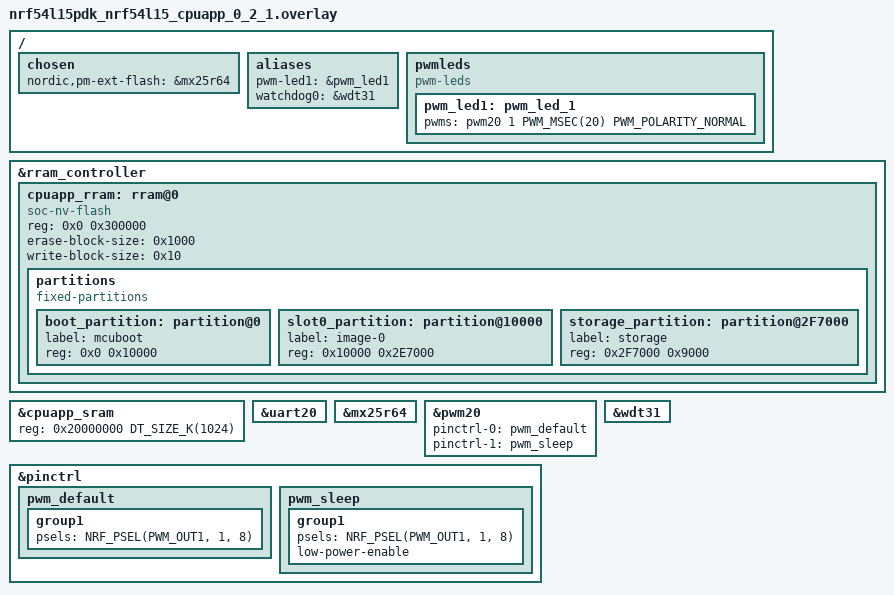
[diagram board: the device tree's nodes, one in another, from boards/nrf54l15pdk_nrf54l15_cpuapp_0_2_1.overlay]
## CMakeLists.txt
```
#
# Copyright (c) 2021 Nordic Semiconductor ASA
#
# SPDX-License-Identifier: LicenseRef-Nordic-5-Clause
#

cmake_minimum_required(VERSION 3.20.0)

find_package(Zephyr HINTS $ENV{ZEPHYR_BASE})

project(matter-light-bulb)

# Enable GNU STD support.
include(${ZEPHYR_CONNECTEDHOMEIP_MODULE_DIR}/config/nrfconnect/app/enable-gnu-std.cmake)

# NORDIC SDK APP START

# Include all source files that are located in the Matter common directory.
include(${ZEPHYR_NRF_MODULE_DIR}/samples/matter/common/cmake/source_common.cmake)

# Include Data Model utils
include(${ZEPHYR_NRF_MODULE_DIR}/samples/matter/common/cmake/data_model.cmake)

target_include_directories(app PRIVATE
    src
)

if(CONFIG_AWS_IOT_INTEGRATION)
    add_subdirectory(src/aws_iot_integration)
endif()

target_sources(app PRIVATE
    src/app_task.cpp
    src/main.cpp
    src/zcl_callbacks.cpp
    ${CHIP_ROOT}/src/app/util/persistence/DeferredAttributePersistenceProvider.cpp
)

ncs_configure_data_model()
# NORDIC SDK APP END
```

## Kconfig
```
#
# Copyright (c) 2022 Nordic Semiconductor
#
# SPDX-License-Identifier: LicenseRef-Nordic-5-Clause
#
mainmenu "Matter nRF Connect Light Bulb Example Application"

# Sample configuration used for Thread networking
if NET_L2_OPENTHREAD

choice OPENTHREAD_NORDIC_LIBRARY_CONFIGURATION
	default OPENTHREAD_NORDIC_LIBRARY_MTD
endchoice

choice OPENTHREAD_DEVICE_TYPE
	default OPENTHREAD_MTD
endchoice

config CHIP_ENABLE_SLEEPY_END_DEVICE_SUPPORT
	bool
	default y

endif # NET_L2_OPENTHREAD

if MPSL_FEM

config OPENTHREAD_DEFAULT_TX_POWER
	int "Set the default 802.15.4 output power (dBm) for device with FEM"
	range -40 20
	default 20
	help
	  Use this setting to set the default Thread (802.15.4) output power for device that
	  uses FEM. This value has a unit in dBm and represents the Tx power at Antenna port of FEM device.

# override FEM GAIN to 20 dB as a default
# see subsys/mpsl/fem/Kconfig
# Leave MPSL_FEM_NRF21540_TX_GAIN_DB unchanged when OPENTHREAD_DEFAULT_TX_POWER=0
# to set the output power to a similar value as for nRF52840DK.
config MPSL_FEM_NRF21540_TX_GAIN_DB
	default 20 if OPENTHREAD_DEFAULT_TX_POWER != 0

endif # MPSL_FEM

source "${ZEPHYR_BASE}/../modules/lib/matter/config/nrfconnect/chip-module/Kconfig.features"
source "${ZEPHYR_BASE}/../modules/lib/matter/config/nrfconnect/chip-module/Kconfig.defaults"
source "Kconfig.zephyr"
```

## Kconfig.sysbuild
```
#
# Copyright (c) 2023 Nordic Semiconductor ASA
#
# SPDX-License-Identifier: LicenseRef-Nordic-5-Clause
#

config PARTITION_MANAGER
	default n if SOC_SERIES_NRF52X || SOC_NRF54L15 || SOC_NRF54LM20A

# This config has to be enabled manually for variants with shields, because sysbuild does not support it.
config WIFI_NRF70
	default y if BOARD_NRF7002DK

#### Radio core selection
config NRF_DEFAULT_IPC_RADIO
	default y

# Enable IEEE802.15.4 serialization to network core
# This config automatically pulls in the `overlay-802154.conf` in the ipc_radio image
config NETCORE_IPC_RADIO_IEEE802154
	default y if SOC_SERIES_NRF53X && !WIFI_NRF70

# Enable Bluetooth serialization to network core
# This config automatically pulls in the `overlay-bt_hci_ipc.conf` in the ipc_radio image
config NETCORE_IPC_RADIO_BT_HCI_IPC
	default y if SOC_SERIES_NRF53X

#### Bootloader
choice BOOTLOADER
	default BOOTLOADER_MCUBOOT if !BOARD_NRF21540DK
endchoice

if BOOTLOADER_MCUBOOT

#### DFU multi-image support
config DFU_MULTI_IMAGE_PACKAGE_BUILD
	default y

config DFU_MULTI_IMAGE_PACKAGE_APP
	default y

config PM_EXTERNAL_FLASH_MCUBOOT_SECONDARY
	default y

#### DFU network core configuration
if SOC_SERIES_NRF53X

choice MCUBOOT_MODE
	default MCUBOOT_MODE_OVERWRITE_ONLY
endchoice

choice BOOT_SIGNATURE_TYPE
	default BOOT_SIGNATURE_TYPE_RSA
endchoice

config SECURE_BOOT_NETCORE
	default y

config NETCORE_APP_UPDATE
	default y

config DFU_MULTI_IMAGE_PACKAGE_NET
	default y

if BOARD_NRF54L15DK || BOARD_NRF54LM20DK

# Disable checking the external drivers for nRF54L15 and nRF54LM20 DKs.
config PM_OVERRIDE_EXTERNAL_DRIVER_CHECK
	default y

endif # BOARD_NRF54L15DK || BOARD_NRF54LM20DK

endif # BOOTLOADER_MCUBOOT

# Store the Wi-Fi firmware patch on external flash by default for nRF5340 with nRF7002
if WIFI_NRF70 && SOC_NRF5340_CPUAPP

choice WIFI_PATCHES_EXT_FLASH_SUPPORT
	default WIFI_PATCHES_EXT_FLASH_STORE

endchoice

config DFU_MULTI_IMAGE_PACKAGE_WIFI_FW_PATCH
	default y

endif # WIFI_NRF70

endif # SOC_SERIES_NRF53X

#### Enable generating factory data
config MATTER_FACTORY_DATA_GENERATE
	default y if !BOARD_NRF21540DK

source "share/sysbuild/Kconfig"
```

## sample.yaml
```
sample:
  description: Matter Light Bulb example
  name: Matter Light Bulb
tests:
  sample.matter.light_bulb.release:
    sysbuild: true
    build_only: true
    extra_args: FILE_SUFFIX=release
      SB_CONFIG_BOOTLOADER_MCUBOOT=y SB_CONFIG_PARTITION_MANAGER=y
    integration_platforms:
      - nrf52840dk/nrf52840
      - nrf5340dk/nrf5340/cpuapp
      - nrf7002dk/nrf5340/cpuapp
      - nrf54l15pdk/nrf54l15/cpuapp
      - nrf54l15pdk@0.3.0/nrf54l15/cpuapp
    platform_allow: nrf52840dk/nrf52840 nrf5340dk/nrf5340/cpuapp nrf7002dk/nrf5340/cpuapp
      nrf54l15pdk/nrf54l15/cpuapp nrf54l15pdk@0.3.0/nrf54l15/cpuapp
    tags: sysbuild
  sample.matter.light_bulb.ffs:
    sysbuild: true
    build_only: true
    extra_args: >
      CONFIG_CHIP_COMMISSIONABLE_DEVICE_TYPE=y CONFIG_CHIP_ROTATING_DEVICE_ID=y
      CONFIG_CHIP_DEVICE_TYPE=257
    integration_platforms:
      - nrf52840dk/nrf52840
      - nrf5340dk/nrf5340/cpuapp
      - nrf7002dk/nrf5340/cpuapp
    platform_allow: nrf52840dk/nrf52840 nrf5340dk/nrf5340/cpuapp nrf7002dk/nrf5340/cpuapp
    tags: sysbuild
  sample.matter.light_bulb.debug.nrf21540ek:
    sysbuild: true
    build_only: true
    extra_args: light_bulb_SHIELD=nrf21540ek
    integration_platforms:
      - nrf52840dk/nrf52840
    platform_allow: nrf52840dk/nrf52840
    tags: sysbuild
  sample.matter.light_bulb.debug.nrf21540ek_fwd:
    sysbuild: true
    build_only: true
    extra_args: light_bulb_SHIELD=nrf21540ek_fwd multiprotocol_rpmsg_SHIELD=nrf21540ek
    integration_platforms:
      - nrf5340dk/nrf5340/cpuapp
    platform_allow: nrf5340dk/nrf5340/cpuapp
    tags: sysbuild
  # Sample to execute load tests
  sample.matter.light_bulb.persistent_subscriptions:
    sysbuild: true
    build_only: true
    extra_args: CONFIG_CHIP_PERSISTENT_SUBSCRIPTIONS=y
    platform_allow: nrf52840dk/nrf52840 nrf5340dk/nrf5340/cpuapp nrf7002dk/nrf5340/cpuapp
    integration_platforms:
      - nrf52840dk/nrf52840
      - nrf5340dk/nrf5340/cpuapp
      - nrf7002dk/nrf5340/cpuapp
    tags: sysbuild
  sample.matter.light_bulb.aws:
    sysbuild: true
    build_only: true
    extra_args: EXTRA_CONF_FILE="overlay-aws-iot-integration.conf"
    platform_allow: nrf7002dk/nrf5340/cpuapp
    integration_platforms:
      - nrf7002dk/nrf5340/cpuapp
    tags: sysbuild
  sample.matter.light_bulb.memory_profiling:
    sysbuild: true
    build_only: true
    extra_args: CONFIG_CHIP_MEMORY_PROFILING=y CONFIG_SHELL_MINIMAL=y
    platform_allow: nrf52840dk/nrf52840 nrf5340dk/nrf5340/cpuapp nrf7002dk/nrf5340/cpuapp
    integration_platforms:
      - nrf52840dk/nrf52840
      - nrf5340dk/nrf5340/cpuapp
      - nrf7002dk/nrf5340/cpuapp
    tags: sysbuild
```

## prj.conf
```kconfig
#
# Copyright (c) 2022 Nordic Semiconductor ASA
#
# SPDX-License-Identifier: LicenseRef-Nordic-5-Clause
#

# Enable CHIP

# Configure ZAP file name
CONFIG_NCS_SAMPLE_MATTER_ZAP_FILE_PATH="${APPLICATION_CONFIG_DIR}/src/default_zap/light_bulb.zap"

# 32773 == 0x8005 (example lighting-app)
CONFIG_CHIP_DEVICE_PRODUCT_ID=32773
CONFIG_STD_CPP17=y

# Enable Matter pairing automatically on application start.
CONFIG_CHIP_ENABLE_PAIRING_AUTOSTART=y

# Enable Matter extended announcement and increase duration to 1 hour.
CONFIG_CHIP_BLE_EXT_ADVERTISING=y
CONFIG_CHIP_BLE_ADVERTISING_DURATION=60

# Add support for LEDs and buttons on Nordic development kits
CONFIG_DK_LIBRARY=y
CONFIG_PWM=y

# Bluetooth Low Energy configuration
CONFIG_BT_DEVICE_NAME="MatterLight"

# Other settings
CONFIG_THREAD_NAME=y
CONFIG_MPU_STACK_GUARD=y
CONFIG_RESET_ON_FATAL_ERROR=n
CONFIG_CHIP_LIB_SHELL=y
CONFIG_NCS_SAMPLE_MATTER_TEST_SHELL=y

# Reduce application size
CONFIG_USE_SEGGER_RTT=n

# Enable Factory Data feature
CONFIG_CHIP_FACTORY_DATA=y
CONFIG_CHIP_FACTORY_DATA_BUILD=y
```

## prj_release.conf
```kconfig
#
# Copyright (c) 2022 Nordic Semiconductor ASA
#
# SPDX-License-Identifier: LicenseRef-Nordic-5-Clause
#

# Enable CHIP
CONFIG_CHIP=y
CONFIG_CHIP_PROJECT_CONFIG="src/chip_project_config.h"
# 32773 == 0x8005 (example lighting-app)
CONFIG_CHIP_DEVICE_PRODUCT_ID=32773
CONFIG_STD_CPP17=y

# Enable Matter pairing automatically on application start.
CONFIG_CHIP_ENABLE_PAIRING_AUTOSTART=y

# Enable Matter extended announcement and increase duration to 1 hour.
CONFIG_CHIP_BLE_EXT_ADVERTISING=y
CONFIG_CHIP_BLE_ADVERTISING_DURATION=60

# Add support for LEDs and buttons on Nordic development kits
CONFIG_DK_LIBRARY=y
CONFIG_PWM=y

# Bluetooth Low Energy configuration
CONFIG_BT_DEVICE_NAME="MatterLight"

# Enable system reset on fatal error
CONFIG_RESET_ON_FATAL_ERROR=y

# Disable all debug features
CONFIG_USE_SEGGER_RTT=n
CONFIG_SHELL=n
CONFIG_OPENTHREAD_SHELL=n
CONFIG_CONSOLE=n
CONFIG_UART_CONSOLE=n
CONFIG_SERIAL=n
CONFIG_LOG=n
CONFIG_LOG_MODE_MINIMAL=n
CONFIG_ASSERT_VERBOSE=n
CONFIG_ASSERT_NO_FILE_INFO=y
CONFIG_PRINTK=n
CONFIG_PRINTK_SYNC=n
CONFIG_THREAD_NAME=n
CONFIG_BOOT_BANNER=n

# Enable Factory Data feature
CONFIG_CHIP_FACTORY_DATA=y
CONFIG_CHIP_FACTORY_DATA_BUILD=y

# Enable Watchdog
CONFIG_NCS_MATTER_WATCHDOG=y

# Enable LTO to decrease the flash usage.
CONFIG_LTO=y
CONFIG_ISR_TABLES_LOCAL_DECLARATION=y
```

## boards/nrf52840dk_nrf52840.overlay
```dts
/*
 * Copyright (c) 2021-2022 Nordic Semiconductor ASA
 *
 * SPDX-License-Identifier: LicenseRef-Nordic-5-Clause
 */

#include "../../common/boards/nrf52840dk_nrf52840_partitions.dtsi"

/ {
	/*
	* By default, PWM module is only configured for led0 (LED1 on the board).
	* The light bulb app, however, uses LED2 to show the state of the lighting,
	* including its brightness level.
	*/
	aliases {
		pwm-led1 = &pwm_led1;
	};

	pwmleds {
		pwm_led1: pwm_led_1 {
			pwms = <&pwm0 1 PWM_MSEC(20) PWM_POLARITY_INVERTED>;
		};
	};

};

&pwm0 {
	pinctrl-0 = <&pwm0_default_alt>;
	pinctrl-1 = <&pwm0_sleep_alt>;
	pinctrl-names = "default", "sleep";
};

&pinctrl {
	pwm0_default_alt: pwm0_default_alt {
		group1 {
			psels = <NRF_PSEL(PWM_OUT1, 0, 14)>;
			nordic,invert;
		};
	};

	pwm0_sleep_alt: pwm0_sleep_alt {
		group1 {
			psels = <NRF_PSEL(PWM_OUT1, 0, 14)>;
			low-power-enable;
		};
	};

};

/* Disable unused peripherals to reduce power consumption */
&adc {
	status = "disabled";
};

&uart1 {
	status = "disabled";
};

&i2c0 {
	status = "disabled";
};

&spi1 {
	status = "disabled";
};

&spi3 {
	status = "disabled";
};

&usbd {
	status = "disabled";
};
```

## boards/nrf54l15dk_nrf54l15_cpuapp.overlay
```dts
/*
 * Copyright (c) 2024 Nordic Semiconductor ASA
 *
 * SPDX-License-Identifier: LicenseRef-Nordic-5-Clause
 */

#include "../../common/boards/nrf54l15dk_nrf54l15_cpuapp_partitions.dtsi"

/ {
	aliases {
		/* Configure PWM module for led1 (LED2 on the board) */
		pwm-led1 = &pwm_led1;

		/* Use watchdog wdt31 as the application watchdog */
		watchdog0 = &wdt31;
	};

	pwmleds {
		compatible = "pwm-leds";
		pwm_led1: pwm_led_1 {
			pwms = <&pwm20 1 PWM_MSEC(20) PWM_POLARITY_NORMAL>;
		};
	};
};

/* TODO: re-enable HWFC once it's fixed */
&uart20 {
	/delete-property/ hw-flow-control;
};

&pwm20 {
	status = "okay";
	pinctrl-0 = <&pwm_default>;
	pinctrl-1 = <&pwm_sleep>;
	pinctrl-names = "default", "sleep";
};

&pinctrl {
	pwm_default: pwm_default {
		group1 {
			psels = <NRF_PSEL(PWM_OUT1, 1, 10)>;
		};
	};
	pwm_sleep: pwm_sleep {
		group1 {
			psels = <NRF_PSEL(PWM_OUT1, 1, 10)>;
			low-power-enable;
		};
	};
};

&wdt31 {
	status = "okay";
};
```

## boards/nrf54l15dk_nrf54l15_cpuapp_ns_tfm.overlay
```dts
/*
 * Copyright (c) 2024 Nordic Semiconductor ASA
 *
 * SPDX-License-Identifier: LicenseRef-Nordic-5-Clause
 */

#include <samples/matter/nrf54l15_cpuapp_tfm_base_partitions.dtsi>
#include <samples/matter/nrf54l15_cpuapp_tfm_application_partitions.dtsi>

/ {
	aliases {
		/* Use watchdog wdt31 as the application watchdog */
		watchdog0 = &wdt31;
	};

	chosen {
		nordic,pm-ext-flash = &mx25r64;
	};
};

&mx25r64 {
	status = "okay";
};

&wdt31 {
	status = "okay";
};

/* Change IRQ ids to handle button interrupts.
 * The default values for nRF54L15 are 219 and 269,
 * but with TF-M they are reserved for the secure domain
 * (218 and 268 are reserved for the non-secure domain).
 */
&gpiote20 {
	interrupts = <218 NRF_DEFAULT_IRQ_PRIORITY>;
};

&gpiote30 {
	interrupts = <268 NRF_DEFAULT_IRQ_PRIORITY>;
};
```

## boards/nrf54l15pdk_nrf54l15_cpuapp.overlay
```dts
/*
 * Copyright (c) 2024 Nordic Semiconductor ASA
 *
 * SPDX-License-Identifier: LicenseRef-Nordic-5-Clause
 */


/ {
	chosen {
		nordic,pm-ext-flash = &mx25r64;
	};

	aliases {
		// Configure PWM module for led1 (LED2 on the board)
		pwm-led1 = &pwm_led1;

		// Use watchdog wdt31 as the application watchdog
		watchdog0 = &wdt31;
	};

	pwmleds {
		compatible = "pwm-leds";
		pwm_led1: pwm_led_1 {
			pwms = <&pwm20 1 PWM_MSEC(20) PWM_POLARITY_NORMAL>;
		};
	};
};

// Extend RRAM size to 3MB
&cpuapp_rram {
	reg = <0x0 DT_SIZE_K(3072)>;
};

// Extend RAM to 1 MB
&cpuapp_sram {
	reg = <0x20000000 DT_SIZE_K(1024)>;
	ranges = <0x0 0x20000000  0x100000>;
};

// TODO: re-enable HWFC once it's fixed
&uart20 {
	/delete-property/ hw-flow-control;
};

&mx25r64 {
	status = "okay";
};

&pwm20 {
	status = "okay";
	pinctrl-0 = <&pwm_default>;
	pinctrl-1 = <&pwm_sleep>;
	pinctrl-names = "default", "sleep";
};

&pinctrl {
	pwm_default: pwm_default {
		group1 {
			psels = <NRF_PSEL(PWM_OUT1, 1, 10)>;
		};
	};
	pwm_sleep: pwm_sleep {
		group1 {
			psels = <NRF_PSEL(PWM_OUT1, 1, 10)>;
			low-power-enable;
		};
	};
};

&wdt31 {
	status = "okay";
};
```

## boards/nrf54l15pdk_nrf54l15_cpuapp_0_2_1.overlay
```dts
/*
 * Copyright (c) 2024 Nordic Semiconductor ASA
 *
 * SPDX-License-Identifier: LicenseRef-Nordic-5-Clause
 */

/ {
	chosen {
		nordic,pm-ext-flash = &mx25r64;
	};

	aliases {
		// Configure PWM module for led1 (LED2 on the board)
		pwm-led1 = &pwm_led1;

		// Use watchdog wdt31 as the application watchdog
		watchdog0 = &wdt31;
	};

	pwmleds {
		compatible = "pwm-leds";
		pwm_led1: pwm_led_1 {
			pwms = <&pwm20 1 PWM_MSEC(20) PWM_POLARITY_NORMAL>;
		};
	};
};

/delete-node/ &cpuapp_rram;

// Extend RRAM size to 3MB
&rram_controller {
	cpuapp_rram: rram@0 {
		compatible = "soc-nv-flash";
		reg = < 0x0 0x300000 >;
		erase-block-size = < 0x1000 >;
		write-block-size = < 0x10 >;
		partitions {
			compatible = "fixed-partitions";
			#address-cells = < 0x1 >;
			#size-cells = < 0x1 >;
			boot_partition: partition@0 {
				label = "mcuboot";
				reg = < 0x0 0x10000 >;
			};
			slot0_partition: partition@10000 {
				label = "image-0";
				reg = < 0x10000 0x2E7000 >;
			};
			storage_partition: partition@2F7000 {
				label = "storage";
				reg = < 0x2F7000 0x9000 >;
			};
		};
	};
};

// Extend RAM to 1 MB
&cpuapp_sram {
	reg = <0x20000000 DT_SIZE_K(1024)>;
	ranges = <0x0 0x20000000  0x100000>;
};

// TODO: re-enable HWFC once it's fixed
&uart20 {
	/delete-property/ hw-flow-control;
};

&mx25r64 {
	status = "okay";
};

&pwm20 {
	status = "okay";
	pinctrl-0 = <&pwm_default>;
	pinctrl-1 = <&pwm_sleep>;
	pinctrl-names = "default", "sleep";
};

&pinctrl {
	pwm_default: pwm_default {
		group1 {
			psels = <NRF_PSEL(PWM_OUT1, 1, 8)>;
		};
	};
	pwm_sleep: pwm_sleep {
		group1 {
			psels = <NRF_PSEL(PWM_OUT1, 1, 8)>;
			low-power-enable;
		};
	};
};

&wdt31 {
	status = "okay";
};
```

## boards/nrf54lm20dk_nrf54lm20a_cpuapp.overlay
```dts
/*
 * Copyright (c) 2025 Nordic Semiconductor ASA
 *
 * SPDX-License-Identifier: LicenseRef-Nordic-5-Clause
 */

#include "../../common/boards/nrf54lm20dk_nrf54lm20a_cpuapp_partitions.dtsi"

/ {
	aliases {
		/* Configure PWM module for led1 (LED2 on the board) */
		pwm-led1 = &pwm_led1;

		/* Use watchdog wdt31 as the application watchdog */
		watchdog0 = &wdt31;
	};

	pwmleds {
		compatible = "pwm-leds";

		pwm_led1: pwm_led_1 {
			pwms = <&pwm20 1 PWM_MSEC(20) PWM_POLARITY_NORMAL>;
		};
	};
};

&pwm20 {
	status = "okay";
	pinctrl-0 = <&pwm_default>;
	pinctrl-1 = <&pwm_sleep>;
	pinctrl-names = "default", "sleep";
};

&pinctrl {
	pwm_default: pwm_default {
		group1 {
			psels = <NRF_PSEL(PWM_OUT1, 1, 25)>;
		};
	};

	pwm_sleep: pwm_sleep {
		group1 {
			psels = <NRF_PSEL(PWM_OUT1, 1, 25)>;
			low-power-enable;
		};
	};
};

&wdt31 {
	status = "okay";
};
```

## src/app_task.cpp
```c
/*
 * Copyright (c) 2021 Nordic Semiconductor ASA
 *
 * SPDX-License-Identifier: LicenseRef-Nordic-5-Clause
 */

#include "app_task.h"

#include "app_config.h"
#include "led_util.h"
#include "pwm_device.h"

#include <platform/CHIPDeviceLayer.h>

#include <app-common/zap-generated/attribute-id.h>
#include <app-common/zap-generated/attribute-type.h>
#include <app-common/zap-generated/attributes/Accessors.h>
#include <app-common/zap-generated/cluster-id.h>
#include <app/DeferredAttributePersistenceProvider.h>
#include <app/clusters/identify-server/identify-server.h>
#include <app/server/OnboardingCodesUtil.h>
#include <app/server/Server.h>
#include <credentials/DeviceAttestationCredsProvider.h>
#include <credentials/examples/DeviceAttestationCredsExample.h>
#include <lib/support/CHIPMem.h>
#include <lib/support/CodeUtils.h>
#include <system/SystemError.h>

#ifdef CONFIG_CHIP_WIFI
#include <app/clusters/network-commissioning/network-commissioning.h>
#include <platform/nrfconnect/wifi/NrfWiFiDriver.h>
#endif

#ifdef CONFIG_CHIP_OTA_REQUESTOR
#include "ota_util.h"
#endif

#include <dk_buttons_and_leds.h>
#include <zephyr/logging/log.h>
#include <zephyr/kernel.h>

LOG_MODULE_DECLARE(app, CONFIG_MATTER_LOG_LEVEL);

using namespace ::chip;
using namespace ::chip::app;
using namespace ::chip::Credentials;
using namespace ::chip::DeviceLayer;

namespace
{
constexpr uint32_t kFactoryResetTriggerTimeout = 3000;
constexpr uint32_t kFactoryResetCancelWindowTimeout = 3000;
constexpr size_t kAppEventQueueSize = 10;
constexpr EndpointId kLightEndpointId = 1;
constexpr uint8_t kDefaultMinLevel = 0;
constexpr uint8_t kDefaultMaxLevel = 254;
#if NUMBER_OF_BUTTONS == 2
constexpr uint32_t kAdvertisingTriggerTimeout = 3000;
#endif

K_MSGQ_DEFINE(sAppEventQueue, sizeof(AppEvent), kAppEventQueueSize, alignof(AppEvent));
k_timer sFunctionTimer;

Identify sIdentify = { kLightEndpointId, AppTask::IdentifyStartHandler, AppTask::IdentifyStopHandler,
		       EMBER_ZCL_IDENTIFY_IDENTIFY_TYPE_VISIBLE_LED };

LEDWidget sStatusLED;
LEDWidget sIdentifyLED;
#if NUMBER_OF_LEDS == 4
FactoryResetLEDsWrapper<2> sFactoryResetLEDs{ { FACTORY_RESET_SIGNAL_LED, FACTORY_RESET_SIGNAL_LED1 } };
#endif

bool sIsNetworkProvisioned = false;
bool sIsNetworkEnabled = false;
bool sHaveBLEConnections = false;

const struct pwm_dt_spec sLightPwmDevice = PWM_DT_SPEC_GET(DT_ALIAS(pwm_led1));

// Define a custom attribute persister which makes actual write of the CurrentLevel attribute value
// to the non-volatile storage only when it has remained constant for 5 seconds. This is to reduce
// the flash wearout when the attribute changes frequently as a result of MoveToLevel command.
// DeferredAttribute object describes a deferred attribute, but also holds a buffer with a value to
// be written, so it must live so long as the DeferredAttributePersistenceProvider object.
DeferredAttribute gCurrentLevelPersister(ConcreteAttributePath(kLightEndpointId, Clusters::LevelControl::Id,
							       Clusters::LevelControl::Attributes::CurrentLevel::Id));
DeferredAttributePersistenceProvider gDeferredAttributePersister(Server::GetInstance().GetDefaultAttributePersister(),
								 Span<DeferredAttribute>(&gCurrentLevelPersister, 1),
								 System::Clock::Milliseconds32(5000));

} /* namespace */

namespace LedConsts
{
constexpr uint32_t kBlinkRate_ms{ 500 };
constexpr uint32_t kIdentifyBlinkRate_ms{ 500 };

namespace StatusLed
{
	namespace Unprovisioned
	{
		constexpr uint32_t kOn_ms{ 100 };
		constexpr uint32_t kOff_ms{ kOn_ms };
	} /* namespace Unprovisioned */
	namespace Provisioned
	{
		constexpr uint32_t kOn_ms{ 50 };
		constexpr uint32_t kOff_ms{ 950 };
	} /* namespace Provisioned */

} /* namespace StatusLed */
} /* namespace LedConsts */

#ifdef CONFIG_CHIP_WIFI
app::Clusters::NetworkCommissioning::Instance
	sWiFiCommissioningInstance(0, &(NetworkCommissioning::NrfWiFiDriver::Instance()));
#endif

CHIP_ERROR AppTask::Init()
{
	/* Initialize CHIP stack */
	LOG_INF("Init CHIP stack");

	CHIP_ERROR err = chip::Platform::MemoryInit();
	if (err != CHIP_NO_ERROR) {
		LOG_ERR("Platform::MemoryInit() failed");
		return err;
	}

	err = PlatformMgr().InitChipStack();
	if (err != CHIP_NO_ERROR) {
		LOG_ERR("PlatformMgr().InitChipStack() failed");
		return err;
	}

#if defined(CONFIG_NET_L2_OPENTHREAD)
	err = ThreadStackMgr().InitThreadStack();
	if (err != CHIP_NO_ERROR) {
		LOG_ERR("ThreadStackMgr().InitThreadStack() failed: %s", ErrorStr(err));
		return err;
	}

	err = ConnectivityMgr().SetThreadDeviceType(ConnectivityManager::kThreadDeviceType_Router);

	if (err != CHIP_NO_ERROR) {
		LOG_ERR("ThreadStackMgr().InitThreadStack() failed: %s", ErrorStr(err));
		return err;
	}

#elif defined(CONFIG_CHIP_WIFI)
	sWiFiCommissioningInstance.Init();
#else
	return CHIP_ERROR_INTERNAL;
#endif /* CONFIG_NET_L2_OPENTHREAD */

	/* Initialize LEDs */
	LEDWidget::InitGpio();
	LEDWidget::SetStateUpdateCallback(LEDStateUpdateHandler);

	sStatusLED.Init(SYSTEM_STATE_LED);
	sIdentifyLED.Init(LIGHTING_STATE_LED);
	sIdentifyLED.Set(false);

	UpdateStatusLED();

	/* Initialize buttons */
	int ret = dk_buttons_init(ButtonEventHandler);
	if (ret) {
		LOG_ERR("dk_buttons_init() failed");
		return chip::System::MapErrorZephyr(ret);
	}

	/* Initialize function timer */
	k_timer_init(&sFunctionTimer, &AppTask::FunctionTimerTimeoutCallback, nullptr);
	k_timer_user_data_set(&sFunctionTimer, this);

#ifdef CONFIG_MCUMGR_SMP_BT
	/* Initialize DFU over SMP */
	GetDFUOverSMP().Init(RequestSMPAdvertisingStart);
	GetDFUOverSMP().ConfirmNewImage();
#endif

	/* Initialize lighting device (PWM) */
	uint8_t minLightLevel = kDefaultMinLevel;
	Clusters::LevelControl::Attributes::MinLevel::Get(kLightEndpointId, &minLightLevel);

	uint8_t maxLightLevel = kDefaultMaxLevel;
	Clusters::LevelControl::Attributes::MaxLevel::Get(kLightEndpointId, &maxLightLevel);

	ret = mPWMDevice.Init(&sLightPwmDevice, minLightLevel, maxLightLevel, maxLightLevel);
	if (ret != 0) {
		return chip::System::MapErrorZephyr(ret);
	}
	mPWMDevice.SetCallbacks(ActionInitiated, ActionCompleted);

	/* Initialize CHIP server */
#if CONFIG_CHIP_FACTORY_DATA
	ReturnErrorOnFailure(mFactoryDataProvider.Init());
	SetDeviceInstanceInfoProvider(&mFactoryDataProvider);
	SetDeviceAttestationCredentialsProvider(&mFactoryDataProvider);
	SetCommissionableDataProvider(&mFactoryDataProvider);
#else
	SetDeviceAttestationCredentialsProvider(Examples::GetExampleDACProvider());
#endif

	static CommonCaseDeviceServerInitParams initParams;
	(void)initParams.InitializeStaticResourcesBeforeServerInit();

	ReturnErrorOnFailure(chip::Server::GetInstance().Init(initParams));
	app::SetAttributePersistenceProvider(&gDeferredAttributePersister);
	ConfigurationMgr().LogDeviceConfig();
	PrintOnboardingCodes(chip::RendezvousInformationFlags(chip::RendezvousInformationFlag::kBLE));

	/*
	 * Add CHIP event handler and start CHIP thread.
	 * Note that all the initialization code should happen prior to this point to avoid data races
	 * between the main and the CHIP threads.
	 */
	PlatformMgr().AddEventHandler(ChipEventHandler, 0);

	err = PlatformMgr().StartEventLoopTask();
	if (err != CHIP_NO_ERROR) {
		LOG_ERR("PlatformMgr().StartEventLoopTask() failed");
		return err;
	}

	return CHIP_NO_ERROR;
}

CHIP_ERROR AppTask::StartApp()
{
	ReturnErrorOnFailure(Init());

	AppEvent event = {};

	while (true) {
		k_msgq_get(&sAppEventQueue, &event, K_FOREVER);
		DispatchEvent(event);
	}

	return CHIP_NO_ERROR;
}

void AppTask::IdentifyStartHandler(Identify *)
{
	AppEvent event;
	event.Type = AppEventType::IdentifyStart;
	event.Handler = [](const AppEvent &) {
		Instance().mPWMDevice.SuppressOutput();
		sIdentifyLED.Blink(LedConsts::kIdentifyBlinkRate_ms);
	};
	PostEvent(event);
}

void AppTask::IdentifyStopHandler(Identify *)
{
	AppEvent event;
	event.Type = AppEventType::IdentifyStop;
	event.Handler = [](const AppEvent &) {
		sIdentifyLED.Set(false);
		Instance().mPWMDevice.ApplyLevel();
	};
	PostEvent(event);
}

#if NUMBER_OF_BUTTONS == 2
void AppTask::StartBLEAdvertisementAndLightActionEventHandler(const AppEvent &event)
{
	if (event.ButtonEvent.Action == static_cast<uint8_t>(AppEventType::ButtonPushed)) {
		Instance().StartTimer(kAdvertisingTriggerTimeout);
		Instance().mFunction = FunctionEvent::AdvertisingStart;
	} else {
		if (Instance().mFunction == FunctionEvent::AdvertisingStart && Instance().mFunctionTimerActive) {
			Instance().CancelTimer();
			Instance().mFunction = FunctionEvent::NoneSelected;

			AppEvent button_event;
			button_event.Type = AppEventType::Button;
			button_event.ButtonEvent.PinNo = BLE_ADVERTISEMENT_START_AND_LIGHTING_BUTTON;
			button_event.ButtonEvent.Action = static_cast<uint8_t>(AppEventType::ButtonReleased);
			button_event.Handler = LightingActionEventHandler;
			PostEvent(button_event);
		}
	}
}
#endif

void AppTask::LightingActionEventHandler(const AppEvent &event)
{
	PWMDevice::Action_t action = PWMDevice::INVALID_ACTION;
	int32_t actor = 0;

	if (event.Type == AppEventType::Lighting) {
		action = static_cast<PWMDevice::Action_t>(event.LightingEvent.Action);
		actor = event.LightingEvent.Actor;
	} else if (event.Type == AppEventType::Button) {
		action = Instance().mPWMDevice.IsTurnedOn() ? PWMDevice::OFF_ACTION : PWMDevice::ON_ACTION;
		actor = static_cast<int32_t>(AppEventType::Button);
	}

	if (action != PWMDevice::INVALID_ACTION && Instance().mPWMDevice.InitiateAction(action, actor, NULL)) {
		LOG_INF("Action is already in progress or active.");
	}
}

void AppTask::ButtonEventHandler(uint32_t buttonState, uint32_t hasChanged)
{
	AppEvent button_event;
	button_event.Type = AppEventType::Button;

#if NUMBER_OF_BUTTONS == 2
	if (BLE_ADVERTISEMENT_START_AND_LIGHTING_BUTTON_MASK & hasChanged) {
		button_event.ButtonEvent.PinNo = BLE_ADVERTISEMENT_START_AND_LIGHTING_BUTTON;
		button_event.ButtonEvent.Action =
			static_cast<uint8_t>((BLE_ADVERTISEMENT_START_AND_LIGHTING_BUTTON_MASK & buttonState) ?
						     AppEventType::ButtonPushed :
						     AppEventType::ButtonReleased);
		button_event.Handler = StartBLEAdvertisementAndLightActionEventHandler;
		PostEvent(button_event);
	}
#else
	if (LIGHTING_BUTTON_MASK & buttonState & hasChanged) {
		button_event.ButtonEvent.PinNo = LIGHTING_BUTTON;
		button_event.ButtonEvent.Action = static_cast<uint8_t>(AppEventType::ButtonPushed);
		button_event.Handler = LightingActionEventHandler;
		PostEvent(button_event);
	}

	if (BLE_ADVERTISEMENT_START_BUTTON_MASK & buttonState & hasChanged) {
		button_event.ButtonEvent.PinNo = BLE_ADVERTISEMENT_START_BUTTON;
		button_event.ButtonEvent.Action = static_cast<uint8_t>(AppEventType::ButtonPushed);
		button_event.Handler = StartBLEAdvertisementHandler;
		PostEvent(button_event);
	}
#endif

	if (FUNCTION_BUTTON_MASK & hasChanged) {
		button_event.ButtonEvent.PinNo = FUNCTION_BUTTON;
		button_event.ButtonEvent.Action =
			static_cast<uint8_t>((FUNCTION_BUTTON_MASK & buttonState) ? AppEventType::ButtonPushed :
										    AppEventType::ButtonReleased);
		button_event.Handler = FunctionHandler;
		PostEvent(button_event);
	}
}

void AppTask::FunctionTimerTimeoutCallback(k_timer *timer)
{
	if (!timer) {
		return;
	}

	Instance().mFunctionTimerActive = false;
	AppEvent event;
	event.Type = AppEventType::Timer;
	event.TimerEvent.Context = k_timer_user_data_get(timer);
	event.Handler = FunctionTimerEventHandler;
	PostEvent(event);
}

void AppTask::FunctionTimerEventHandler(const AppEvent &event)
{
	if (event.Type != AppEventType::Timer) {
		return;
	}

	/* If we reached here, the button was held past kFactoryResetTriggerTimeout, initiate factory reset */
	if (Instance().mFunction == FunctionEvent::SoftwareUpdate) {
		LOG_INF("Factory Reset Triggered. Release button within %ums to cancel.", kFactoryResetTriggerTimeout);

		/* Start timer for kFactoryResetCancelWindowTimeout to allow user to cancel, if required. */
		Instance().StartTimer(kFactoryResetCancelWindowTimeout);
		Instance().mFunction = FunctionEvent::FactoryReset;

		/* Turn off all LEDs before starting blink to make sure blink is co-ordinated. */
		sStatusLED.Set(false);
#if NUMBER_OF_LEDS == 4
		sFactoryResetLEDs.Set(false);
#endif

		sStatusLED.Blink(LedConsts::kBlinkRate_ms);
#if NUMBER_OF_LEDS == 4
		sFactoryResetLEDs.Blink(LedConsts::kBlinkRate_ms);
#endif
	} else if (Instance().mFunction == FunctionEvent::FactoryReset) {
		/* Actually trigger Factory Reset */
		Instance().mFunction = FunctionEvent::NoneSelected;
		chip::Server::GetInstance().ScheduleFactoryReset();
	} else if (Instance().mFunction == FunctionEvent::AdvertisingStart) {
		/* The button was held past kAdvertisingTriggerTimeout, start BLE advertisement
		   if we have 2 buttons UI*/
#if NUMBER_OF_BUTTONS == 2
		StartBLEAdvertisementHandler(event);
		Instance().mFunction = FunctionEvent::NoneSelected;
#endif
	}
}

#ifdef CONFIG_MCUMGR_SMP_BT
void AppTask::RequestSMPAdvertisingStart(void)
{
	AppEvent event;
	event.Type = AppEventType::StartSMPAdvertising;
	event.Handler = [](const AppEvent &) { GetDFUOverSMP().StartBLEAdvertising(); };
	PostEvent(event);
}
#endif

void AppTask::FunctionHandler(const AppEvent &event)
{
	if (event.ButtonEvent.PinNo != FUNCTION_BUTTON)
		return;

	/* To trigger software update: press the FUNCTION_BUTTON button briefly (< kFactoryResetTriggerTimeout)
	 * To initiate factory reset: press the FUNCTION_BUTTON for kFactoryResetTriggerTimeout +
	 * kFactoryResetCancelWindowTimeout All LEDs start blinking after kFactoryResetTriggerTimeout to signal factory
	 * reset has been initiated. To cancel factory reset: release the FUNCTION_BUTTON once all LEDs start blinking
	 * within the kFactoryResetCancelWindowTimeout.
	 */
	if (event.ButtonEvent.Action == static_cast<uint8_t>(AppEventType::ButtonPushed)) {
		if (!Instance().mFunctionTimerActive && Instance().mFunction == FunctionEvent::NoneSelected) {
			Instance().StartTimer(kFactoryResetTriggerTimeout);
			Instance().mFunction = FunctionEvent::SoftwareUpdate;
		}
	} else {
		/* If the button was released before factory reset got initiated, trigger a software update. */
		if (Instance().mFunctionTimerActive && Instance().mFunction == FunctionEvent::SoftwareUpdate) {
			Instance().CancelTimer();
			Instance().mFunction = FunctionEvent::NoneSelected;

#ifdef CONFIG_MCUMGR_SMP_BT
			GetDFUOverSMP().StartServer();
#else
			LOG_INF("Software update is disabled");
#endif
		} else if (Instance().mFunctionTimerActive && Instance().mFunction == FunctionEvent::FactoryReset) {
#if NUMBER_OF_LEDS == 4
			sFactoryResetLEDs.Set(false);
#endif
			UpdateStatusLED();
			Instance().CancelTimer();
			Instance().mFunction = FunctionEvent::NoneSelected;
			LOG_INF("Factory Reset has been Canceled");
		}
	}
}

void AppTask::StartBLEAdvertisementHandler(const AppEvent &)
{
	if (Server::GetInstance().GetFabricTable().FabricCount() != 0) {
		LOG_INF("Matter service BLE advertising not started - device is already commissioned");
		return;
	}

	if (ConnectivityMgr().IsBLEAdvertisingEnabled()) {
		LOG_INF("BLE advertising is already enabled");
		return;
	}

	if (Server::GetInstance().GetCommissioningWindowManager().OpenBasicCommissioningWindow() != CHIP_NO_ERROR) {
		LOG_ERR("OpenBasicCommissioningWindow() failed");
	}
}

void AppTask::UpdateLedStateEventHandler(const AppEvent &event)
{
	if (event.Type == AppEventType::UpdateLedState) {
		event.UpdateLedStateEvent.LedWidget->UpdateState();
	}
}

void AppTask::LEDStateUpdateHandler(LEDWidget &ledWidget)
{
	AppEvent event;
	event.Type = AppEventType::UpdateLedState;
	event.Handler = UpdateLedStateEventHandler;
	event.UpdateLedStateEvent.LedWidget = &ledWidget;
	PostEvent(event);
}

void AppTask::UpdateStatusLED()
{
	/* Update the status LED.
	 *
	 * If IPv6 network and service provisioned, keep the LED On constantly.
	 *
	 * If the system has ble connection(s) uptill the stage above, THEN blink the LED at an even
	 * rate of 100ms.
	 *
	 * Otherwise, blink the LED for a very short time. */
	if (sIsNetworkProvisioned && sIsNetworkEnabled) {
		sStatusLED.Set(true);
	} else if (sHaveBLEConnections) {
		sStatusLED.Blink(LedConsts::StatusLed::Unprovisioned::kOn_ms,
				 LedConsts::StatusLed::Unprovisioned::kOff_ms);
	} else {
		sStatusLED.Blink(LedConsts::StatusLed::Provisioned::kOn_ms, LedConsts::StatusLed::Provisioned::kOff_ms);
	}
}

void AppTask::ChipEventHandler(const ChipDeviceEvent *event, intptr_t /* arg */)
{
	switch (event->Type) {
	case DeviceEventType::kCHIPoBLEAdvertisingChange:
#ifdef CONFIG_CHIP_NFC_COMMISSIONING
		if (event->CHIPoBLEAdvertisingChange.Result == kActivity_Started) {
			if (NFCMgr().IsTagEmulationStarted()) {
				LOG_INF("NFC Tag emulation is already started");
			} else {
				ShareQRCodeOverNFC(
					chip::RendezvousInformationFlags(chip::RendezvousInformationFlag::kBLE));
			}
		} else if (event->CHIPoBLEAdvertisingChange.Result == kActivity_Stopped) {
			NFCMgr().StopTagEmulation();
		}
#endif
		sHaveBLEConnections = ConnectivityMgr().NumBLEConnections() != 0;
		UpdateStatusLED();
		break;
#if defined(CONFIG_NET_L2_OPENTHREAD)
	case DeviceEventType::kDnssdPlatformInitialized:
#if CONFIG_CHIP_OTA_REQUESTOR
		InitBasicOTARequestor();
#endif /* CONFIG_CHIP_OTA_REQUESTOR */
		break;
	case DeviceEventType::kThreadStateChange:
		sIsNetworkProvisioned = ConnectivityMgr().IsThreadProvisioned();
		sIsNetworkEnabled = ConnectivityMgr().IsThreadEnabled();
#elif defined(CONFIG_CHIP_WIFI)
	case DeviceEventType::kWiFiConnectivityChange:
		sIsNetworkProvisioned = ConnectivityMgr().IsWiFiStationProvisioned();
		sIsNetworkEnabled = ConnectivityMgr().IsWiFiStationEnabled();
#if CONFIG_CHIP_OTA_REQUESTOR
		if (event->WiFiConnectivityChange.Result == kConnectivity_Established) {
			InitBasicOTARequestor();
		}
#endif /* CONFIG_CHIP_OTA_REQUESTOR */
#endif
		UpdateStatusLED();
		break;
	default:
		break;
	}
}

void AppTask::CancelTimer()
{
	k_timer_stop(&sFunctionTimer);
	mFunctionTimerActive = false;
}

void AppTask::StartTimer(uint32_t timeoutInMs)
{
	k_timer_start(&sFunctionTimer, K_MSEC(timeoutInMs), K_NO_WAIT);
	mFunctionTimerActive = true;
}

void AppTask::ActionInitiated(PWMDevice::Action_t action, int32_t actor)
{
	if (action == PWMDevice::ON_ACTION) {
		LOG_INF("Turn On Action has been initiated");
	} else if (action == PWMDevice::OFF_ACTION) {
		LOG_INF("Turn Off Action has been initiated");
	} else if (action == PWMDevice::LEVEL_ACTION) {
		LOG_INF("Level Action has been initiated");
	}
}

void AppTask::ActionCompleted(PWMDevice::Action_t action, int32_t actor)
{
	if (action == PWMDevice::ON_ACTION) {
		LOG_INF("Turn On Action has been completed");
	} else if (action == PWMDevice::OFF_ACTION) {
		LOG_INF("Turn Off Action has been completed");
	} else if (action == PWMDevice::LEVEL_ACTION) {
		LOG_INF("Level Action has been completed");
	}

	if (actor == static_cast<int32_t>(AppEventType::Button)) {
		Instance().UpdateClusterState();
	}
}

void AppTask::PostEvent(const AppEvent &event)
{
	if (k_msgq_put(&sAppEventQueue, &event, K_NO_WAIT) != 0) {
		LOG_INF("Failed to post event to app task event queue");
	}
}

void AppTask::DispatchEvent(const AppEvent &event)
{
	if (event.Handler) {
		event.Handler(event);
	} else {
		LOG_INF("Event received with no handler. Dropping event.");
	}
}

void AppTask::UpdateClusterState()
{
	SystemLayer().ScheduleLambda([this] {
		/* write the new on/off value */
		EmberAfStatus status =
			Clusters::OnOff::Attributes::OnOff::Set(kLightEndpointId, mPWMDevice.IsTurnedOn());

		if (status != EMBER_ZCL_STATUS_SUCCESS) {
			LOG_ERR("Updating on/off cluster failed: %x", status);
		}

		/* write the current level */
		status = Clusters::LevelControl::Attributes::CurrentLevel::Set(kLightEndpointId, mPWMDevice.GetLevel());

		if (status != EMBER_ZCL_STATUS_SUCCESS) {
			LOG_ERR("Updating level cluster failed: %x", status);
		}
	});
}
```
